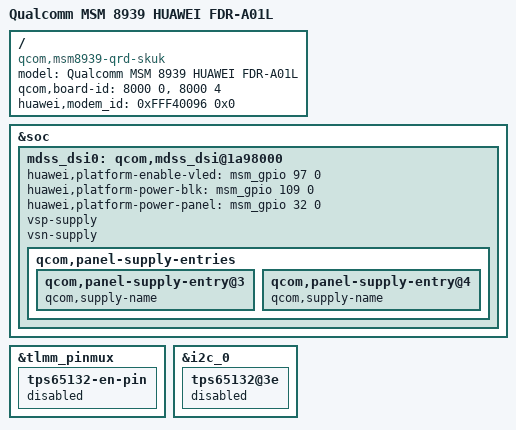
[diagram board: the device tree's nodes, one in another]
/* Copyright (c) 2014, The Linux Foundation. All rights reserved.
 *
 * This program is free software; you can redistribute it and/or modify
 * it under the terms of the GNU General Public License version 2 and
 * only version 2 as published by the Free Software Foundation.
 *
 * This program is distributed in the hope that it will be useful,
 * but WITHOUT ANY WARRANTY; without even the implied warranty of
 * MERCHANTABILITY or FITNESS FOR A PARTICULAR PURPOSE.  See the
 * GNU General Public License for more details.
 */

/dts-v1/;
#include "msm8939-v3.0.dtsi"
#include "msm8939-qrd-skuk.dtsi"
#include "huawei_msm8939_t2_a01l_va/huawei.dtsi"
/ {
	model = "Qualcomm MSM 8939 HUAWEI FDR-A01L";
	compatible = "qcom,msm8939-qrd-skuk", "qcom,msm8939", "qcom,qrd";
	qcom,board-id = <8000 0> , <8000 4>;
	huawei,modem_id = <0xFFF40096 0x0>;
};
/*Rename GPIO*/
&soc {
	mdss_dsi0: qcom,mdss_dsi@1a98000 {

	huawei,platform-enable-vled = <&msm_gpio 97 0>;

	huawei,platform-power-blk = <&msm_gpio 109 0>;

	huawei,platform-power-panel = <&msm_gpio 32 0>;
	};
};

/**************Federer(T2 10) BLSP Configuration Table*******************/
/*	Device_Tree_Node	GPIO	BLSP		Used	Usage	*/
/*	i2c_0			6,7	BLSP2_I2C	Yes	Sensor	*/
/*	i2c_1			2,3	BLSP1_I2C	No	N/A	*/
/*	i2c_4			14,15	BLSP4_I2C	Yes	Battery	*/
/*	i2c_5			18,19	BLSP5_I2C	Yes	TP	*/
/*	i2c_6			22,23	BLSP6_I2C	No	N/A	*/
/*	spi_1			1,2,3,4	BLSP1_SPI	No	N/A	*/
/*	spi_5			16~19	BLSP5_SPI	No	N/A	*/
/*	spi_6			20~23	BLSP6_SPI	No	N/A	*/
/************************************************************************/
&tlmm_pinmux {
	tps65132-en-pin {
		status = "disabled";
	};
};

&i2c_0 {
	tps65132@3e {
		status = "disabled";
	};
};

&mdss_dsi0 {
	vsp-supply;
	vsn-supply;
	qcom,panel-supply-entries {
		qcom,panel-supply-entry@3 {
			qcom,supply-name;
		};
		qcom,panel-supply-entry@4 {
			qcom,supply-name;
		};
	};
};
